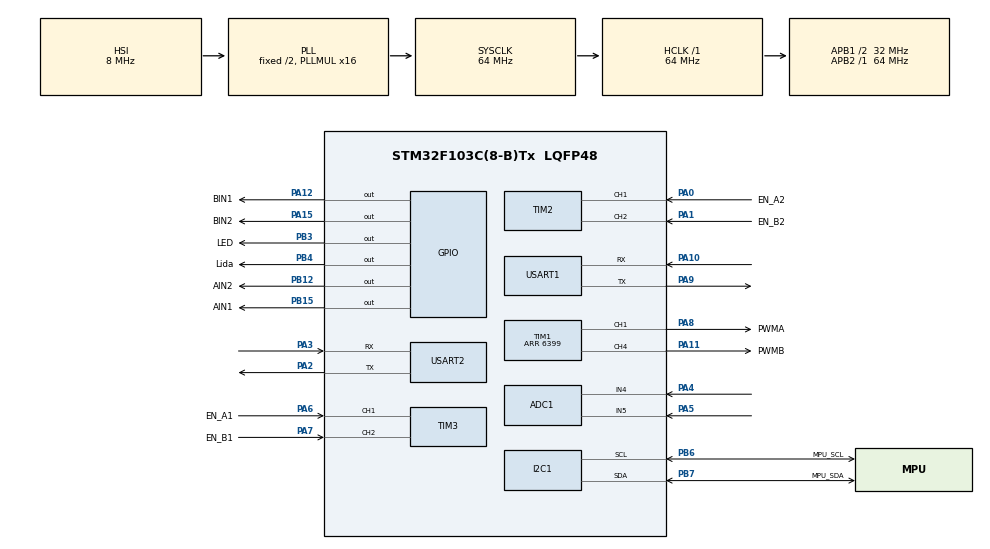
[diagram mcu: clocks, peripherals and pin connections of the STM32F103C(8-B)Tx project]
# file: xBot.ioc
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ADC1.Channel-0\#ChannelRegularConversion=ADC_CHANNEL_5
ADC1.NbrOfConversionFlag=1
ADC1.Rank-0\#ChannelRegularConversion=1
ADC1.SamplingTime-0\#ChannelRegularConversion=ADC_SAMPLETIME_1CYCLE_5
ADC1.master=1
Dma.Request0=USART1_RX
Dma.USART1_RX.0.Direction=DMA_PERIPH_TO_MEMORY
Dma.USART1_RX.0.Instance=DMA1_Channel5
Dma.USART1_RX.0.MemDataAlignment=DMA_MDATAALIGN_BYTE
Dma.USART1_RX.0.MemInc=DMA_MINC_ENABLE
Dma.USART1_RX.0.Mode=DMA_NORMAL
Dma.USART1_RX.0.PeriphDataAlignment=DMA_PDATAALIGN_BYTE
Dma.USART1_RX.0.PeriphInc=DMA_PINC_DISABLE
Dma.USART1_RX.0.Priority=DMA_PRIORITY_LOW
FREERTOS.Tasks01=defaultTask,24,128,StartDefaultTask,Default,NULL,Dynamic,NULL,NULL
FREERTOS.configTOTAL_HEAP_SIZE=12288
I2C1.I2C_Mode=I2C_Fast
Mcu.Family=STM32F1
Mcu.Name=STM32F103C(8-B)Tx
Mcu.Package=LQFP48
NVIC.DMA1_Channel5_IRQn=true\:5\:0\:false\:false\:true\:true\:false\:true\:true
NVIC.PriorityGroup=NVIC_PRIORITYGROUP_4
NVIC.TIM4_IRQn=true\:15\:0\:false\:false\:true\:false\:false\:true\:true
NVIC.TimeBase=TIM4_IRQn
NVIC.TimeBaseIP=TIM4
PA0-WKUP.GPIO_Label=EN_A2
PA0-WKUP.Signal=S_TIM2_CH1_ETR
PA1.GPIO_Label=EN_B2
PA1.Signal=S_TIM2_CH2
PA10.Mode=Asynchronous
PA10.Signal=USART1_RX
PA11.GPIO_Label=PWMB
PA11.Signal=S_TIM1_CH4
PA12.GPIO_Label=BIN1
PA12.Signal=GPIO_Output
PA13.Mode=Serial_Wire
PA13.Signal=SYS_JTMS-SWDIO
PA14.Mode=Serial_Wire
PA14.Signal=SYS_JTCK-SWCLK
PA15.GPIO_Label=BIN2
PA15.Signal=GPIO_Output
PA2.Mode=Asynchronous
PA2.Signal=USART2_TX
PA3.Mode=Asynchronous
PA3.Signal=USART2_RX
PA4.Signal=ADCx_IN4
PA5.Signal=ADCx_IN5
PA6.GPIO_Label=EN_A1
PA6.Signal=S_TIM3_CH1
PA7.GPIO_Label=EN_B1
PA7.Signal=S_TIM3_CH2
PA8.GPIO_Label=PWMA
PA8.Signal=S_TIM1_CH1
PA9.Mode=Asynchronous
PA9.Signal=USART1_TX
PB12.GPIO_Label=AIN2
PB12.Signal=GPIO_Output
PB15.GPIO_Label=AIN1
PB15.Signal=GPIO_Output
PB3.GPIO_Label=LED
PB3.GPIO_Speed=GPIO_SPEED_FREQ_HIGH
PB3.PinState=GPIO_PIN_RESET
PB3.Signal=GPIO_Output
PB4.GPIO_Label=Lida
PB4.Signal=GPIO_Output
PB6.GPIO_Label=MPU_SCL
PB6.Mode=I2C
PB6.Signal=I2C1_SCL
PB7.GPIO_Label=MPU_SDA
PB7.Mode=I2C
PB7.Signal=I2C1_SDA
ProjectManager.HeapSize=0x200
ProjectManager.StackSize=0x400
ProjectManager.TargetToolchain=CMake
RCC.ADCPresc=RCC_ADCPCLK2_DIV6
RCC.AHBFreq_Value=64000000
RCC.APB1CLKDivider=RCC_HCLK_DIV2
RCC.APB1Freq_Value=32000000
RCC.APB1TimFreq_Value=64000000
RCC.APB2Freq_Value=64000000
RCC.APB2TimFreq_Value=64000000
RCC.HCLKFreq_Value=64000000
RCC.PLLMUL=RCC_PLL_MUL16
RCC.SYSCLKFreq_VALUE=64000000
RCC.SYSCLKSource=RCC_SYSCLKSOURCE_PLLCLK
RCC.USBFreq_Value=64000000
SH.ADCx_IN4.0=ADC1_IN4,IN4
SH.ADCx_IN5.0=ADC1_IN5,IN5
SH.S_TIM1_CH1.0=TIM1_CH1,PWM Generation1 CH1
SH.S_TIM1_CH4.0=TIM1_CH4,PWM Generation4 CH4
SH.S_TIM2_CH1_ETR.0=TIM2_CH1,Encoder_Interface
SH.S_TIM2_CH2.0=TIM2_CH2,Encoder_Interface
SH.S_TIM3_CH1.0=TIM3_CH1,Encoder_Interface
SH.S_TIM3_CH2.0=TIM3_CH2,Encoder_Interface
TIM1.Channel-PWM\ Generation1\ CH1=TIM_CHANNEL_1
TIM1.Channel-PWM\ Generation4\ CH4=TIM_CHANNEL_4
TIM1.Period=6399
TIM2.EncoderMode=TIM_ENCODERMODE_TI12
TIM3.EncoderMode=TIM_ENCODERMODE_TI12
USART1.VirtualMode=VM_ASYNC
USART2.VirtualMode=VM_ASYNC
VP_FREERTOS_VS_CMSIS_V2.Mode=CMSIS_V2
VP_SYS_VS_tim4.Mode=TIM4
board=custom

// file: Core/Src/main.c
/* USER CODE BEGIN Header */
/**
  ******************************************************************************
  * @file           : main.c
  * @brief          : Main program body
  ******************************************************************************
  * @attention
  *
  * Copyright (c) 2026 STMicroelectronics.
  * All rights reserved.
  *
  * This software is licensed under terms that can be found in the LICENSE file
  * in the root directory of this software component.
  * If no LICENSE file comes with this software, it is provided AS-IS.
  *
  ******************************************************************************
  */
/* USER CODE END Header */
#include "main.h"
#include "cmsis_os.h"
#include "adc.h"
#include "dma.h"
#include "i2c.h"
#include "tim.h"
#include "usart.h"
#include "gpio.h"

/* USER CODE BEGIN Includes */
#include "imu_drive.h"
/* USER CODE END Includes */

void SystemClock_Config(void);
void MX_FREERTOS_Init(void);

int main(void)
{

  /* MCU Configuration--------------------------------------------------------*/

  /* Reset of all peripherals, Initializes the Flash interface and the Systick. */
  HAL_Init();

  /* Configure the system clock */
  SystemClock_Config();

  /* Initialize all configured peripherals */
  MX_GPIO_Init();
  MX_DMA_Init();
  MX_ADC1_Init();
  MX_TIM1_Init();
  MX_TIM2_Init();
  MX_TIM3_Init();
  MX_USART1_UART_Init();
  MX_USART2_UART_Init();
  MX_I2C1_Init();
  /* USER CODE BEGIN 2 */
  /* MPU init before FreeRTOS — same timing as ref/MPU_Test (bare-metal) */
  (void)imu_drive_init();
  /* Peripheral bring-up for tasks is done in app_main via task_chassis_init(). */
  /* USER CODE END 2 */

  /* Init scheduler */
  osKernelInitialize();  /* Call init function for freertos objects (in cmsis_os2.c) */
  MX_FREERTOS_Init();

  /* Start scheduler */
  osKernelStart();

  /* We should never get here as control is now taken by the scheduler */

  /* Infinite loop */
  while (1)
  {

  }
}

void SystemClock_Config(void)
{
  RCC_OscInitTypeDef RCC_OscInitStruct = {0};
  RCC_ClkInitTypeDef RCC_ClkInitStruct = {0};
  RCC_PeriphCLKInitTypeDef PeriphClkInit = {0};

  /** Initializes the RCC Oscillators according to the specified parameters
  * in the RCC_OscInitTypeDef structure.
  */
  RCC_OscInitStruct.OscillatorType = RCC_OSCILLATORTYPE_HSI;
  RCC_OscInitStruct.HSIState = RCC_HSI_ON;
  RCC_OscInitStruct.HSICalibrationValue = RCC_HSICALIBRATION_DEFAULT;
  RCC_OscInitStruct.PLL.PLLState = RCC_PLL_ON;
  RCC_OscInitStruct.PLL.PLLSource = RCC_PLLSOURCE_HSI_DIV2;
  RCC_OscInitStruct.PLL.PLLMUL = RCC_PLL_MUL16;
  if (HAL_RCC_OscConfig(&RCC_OscInitStruct) != HAL_OK)
  {
    Error_Handler();
  }

  /** Initializes the CPU, AHB and APB buses clocks
  */
  RCC_ClkInitStruct.ClockType = RCC_CLOCKTYPE_HCLK|RCC_CLOCKTYPE_SYSCLK
                              |RCC_CLOCKTYPE_PCLK1|RCC_CLOCKTYPE_PCLK2;
  RCC_ClkInitStruct.SYSCLKSource = RCC_SYSCLKSOURCE_PLLCLK;
  RCC_ClkInitStruct.AHBCLKDivider = RCC_SYSCLK_DIV1;
  RCC_ClkInitStruct.APB1CLKDivider = RCC_HCLK_DIV2;
  RCC_ClkInitStruct.APB2CLKDivider = RCC_HCLK_DIV1;

  if (HAL_RCC_ClockConfig(&RCC_ClkInitStruct, FLASH_LATENCY_2) != HAL_OK)
  {
    Error_Handler();
  }
  PeriphClkInit.PeriphClockSelection = RCC_PERIPHCLK_ADC;
  PeriphClkInit.AdcClockSelection = RCC_ADCPCLK2_DIV6;
  if (HAL_RCCEx_PeriphCLKConfig(&PeriphClkInit) != HAL_OK)
  {
    Error_Handler();
  }
}

void HAL_TIM_PeriodElapsedCallback(TIM_HandleTypeDef *htim)
{
  if (htim->Instance == TIM4)
  {
    HAL_IncTick();
  }
}

void Error_Handler(void)
{
  __disable_irq();
  while (1)
  {
  }
}

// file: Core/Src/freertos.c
/* USER CODE BEGIN Header */
/**
  ******************************************************************************
  * File Name          : freertos.c
  * Description        : Code for freertos applications
  ******************************************************************************
  * @attention
  *
  * Copyright (c) 2026 STMicroelectronics.
  * All rights reserved.
  *
  * This software is licensed under terms that can be found in the LICENSE file
  * in the root directory of this software component.
  * If no LICENSE file comes with this software, it is provided AS-IS.
  *
  ******************************************************************************
  */
/* USER CODE END Header */

#include "FreeRTOS.h"
#include "task.h"
#include "main.h"
#include "cmsis_os.h"

/* USER CODE BEGIN Includes */
#include "app.h"
/* USER CODE END Includes */

/* Definitions for defaultTask */
osThreadId_t defaultTaskHandle;
const osThreadAttr_t defaultTask_attributes = {
  .name = "defaultTask",
  .stack_size = 128 * 4,
  .priority = (osPriority_t) osPriorityNormal,
};

void StartDefaultTask(void *argument);

void MX_FREERTOS_Init(void); /* (MISRA C 2004 rule 8.1) */

void MX_FREERTOS_Init(void) {

  /* Create the thread(s) */
  /* creation of defaultTask */
  defaultTaskHandle = osThreadNew(StartDefaultTask, NULL, &defaultTask_attributes);

}

void StartDefaultTask(void *argument)
{
  /* USER CODE BEGIN StartDefaultTask */
  (void)argument;
  app_main();
  osThreadExit();
  /* USER CODE END StartDefaultTask */
}
